# wsoc_wgcm_secure register map
Vendor: Texas Instruments
Peripheral module from a debugger description file (folder CC35X1).
Registers are 32-bit, read-write, no defined reset value unless marked. A register's access mark holds for its fields unless they carry their own. Offsets are as the file gives them; lines under a group give offsets from that group; [hi:lo] are bit positions; {n}, {i} and the like mark numbered series; 'fields as' and 'values as' point back to an identical list; <NAME> marks a mode.

## wsoc_wgcm_secure
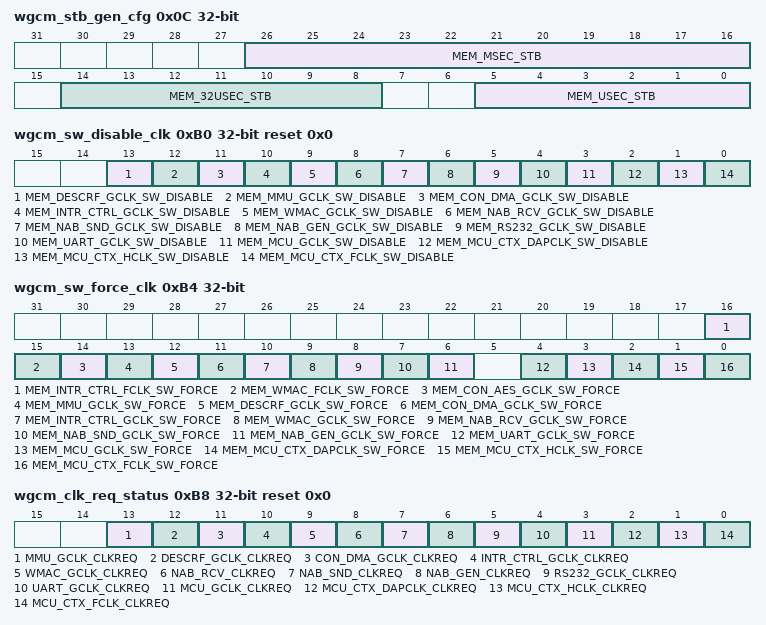
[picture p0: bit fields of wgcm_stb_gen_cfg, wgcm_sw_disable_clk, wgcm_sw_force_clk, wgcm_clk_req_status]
0x0C wgcm_stb_gen_cfg access per field — configuration of usec strobe value represent number of main ocp clocks per usec strobe. if clock frequency changes, the usec strobe will drift with it.
  [26:16] MEM_MSEC_STB rw — number of usec stb used in order to generage a 1 msec period
  [14:8] MEM_32USEC_STB rw — number of usec_stb to count per pulse. cfg should be 1 less than required (31 for 32 usec)
  [5:0] MEM_USEC_STB rw — number of wsoc ocp clocks to count per usec. (cfg should be 1 less that required - 19 for 20 clocks)
0x2C gns_spare_reg access per field — clock enable for the BLE. 0 - clock disabled. 1 - clock enabled.
  [7:0] MEM_GNS_SPARE rw
{0x40+8i} gns_notification_{i}_value (i=0..3)
  [31:0] MEM_GNS_NOTIF_{i}_VALUE
{0x44+8i} gns_notification_{i}_enable (i=0..3)
  [31:0] MEM_GNS_NOTIF_{i}_EN
0x60 gns_notification_status access per field
  [3:0] MEM_GNS_NOTIF_STATUS_RDCL rw — Bit 0 - gns notification 0 Bit 1 - gns notification 1 Bit 2 - gns notification 2 Bit 3 - gns notification 3
0x70 gns_raw_status ro reset 0x0 — GNS_RAW_STATUS - LSB (31:0) [ 0] = wgcm_in_nab_is_pending_recv_or_evt [ 1] = wgcm_in_nab_is_busy [ 2] = wgcm_in_descrf_rx_nab_done_qne [ 3] = |mem_wgcm_in_sw_src[3:0] [ 4] = wgcm_wrapper_is_busy [ 5] = mem_force_core_on [ 6] = ble_gns_busy [ 7] = debugss_core_forceactive [ 8] = queue_not_empty_m0_sw_usage_irq[0] [ 9] = queue_not_empty_m0_sw_usage_irq[1] [10] = queue_not_empty_m0_sw_usage_irq[2] [11] = queue_not_empty_m0_sw_usage_irq[3] [12] = queue_not_empty_m0_sw_usage_irq[4] [13] = queue_not_empty_m0_sw_usage_irq[5] [14] = queue_not_empty_m0_sw_usage_irq[6] [15] = queue_not_empty_m0_sw_usage_irq[7] [16] = queue_not_empty_m0_sw_usage_irq[8] [17] = queue_not_empty_m0_sw_usage_irq[9] [18] = queue_not_empty_m3_sw_usage_irq[0] [19] = queue_not_empty_m3_sw_usage_irq[1] [20] = queue_not_empty_m3_sw_usage_irq[2] [21] = queue_not_empty_m3_sw_usage_irq[3] [22] = queue_not_empty_m3_sw_usage_irq[4] [23] = queue_not_empty_m3_sw_usage_irq[5] [24] = queue_not_empty_m3_sw_usage_irq[6] [25] = queue_not_empty_m3_sw_usage_irq[7] [26] = queue_not_empty_m3_sw_usage_irq[8] [27] = hif_tx_busy [28] = hif_rx_busy [29] = hif_dma_active [30] = hif_fifo_not_empty [31] = gns_in_uart_fifo_not_empty
  [31:0] GNS_RAW_STATUS_RDCL — Bit 31
0x74 gns_host_if_trigger ro
  [31:0] MEM_GNS_HOST_IF_TRIGGER_RDCL — [ 0] = wgcm_in_nab_is_pending_recv_or_evt [ 1] = wgcm_in_nab_is_busy [ 2] = wgcm_in_descrf_rx_nab_done_qne [ 3] = |mem_wgcm_in_sw_src[3:0] [ 4] = wgcm_wrapper_is_busy [ 5] = mem_force_core_on [ 6] = ble_gns_busy [ 7] = debugss_core_forceactive [ 8] = queue_not_empty_m0_sw_usage_irq[0] [ 9] = queue_not_empty_m0_sw_usage_irq[1] [10] = queue_not_empty_m0_sw_usage_irq[2] [11] = queue_not_empty_m0_sw_usage_irq[3] [12] = queue_not_empty_m0_sw_usage_irq[4] [13] = queue_not_empty_m0_sw_usage_irq[5] [14] = queue_not_empty_m0_sw_usage_irq[6] [15] = queue_not_empty_m0_sw_usage_irq[7] [16] = queue_not_empty_m0_sw_usage_irq[8] [17] = queue_not_empty_m0_sw_usage_irq[9] [18] = queue_not_empty_m3_sw_usage_irq[0] [19] = queue_not_empty_m3_sw_usage_irq[1] [20] = queue_not_empty_m3_sw_usage_irq[2] [21] = queue_not_empty_m3_sw_usage_irq[3] [22] = queue_not_empty_m3_sw_usage_irq[4] [23] = queue_not_empty_m3_sw_usage_irq[5] [24] = queue_not_empty_m3_sw_usage_irq[6] [25] = queue_not_empty_m3_sw_usage_irq[7] [26] = queue_not_empty_m3_sw_usage_irq[8] [27] = hif_tx_busy [28] = hif_rx_busy [29] = hif_dma_active [30] = hif_fifo_not_empty [31] = gns_in_uart_fifo_not_empty
0x78 gns_host_if_lock access per field
  [0] MEM_GNS_HOST_IF_LOCK_WROPT rw — HOST Lock Status 1 - HOST I/F is locked (Default) 0 - HOST I/F is active This field initiate as "loced", it can be written directly or latched "loced" ('0') while reading "HOST_IF_TRIGGER" field and the field is zero
0x80 gns_host_if_en
  [31:0] MEM_GNS_HOST_IF_EN
0x84 gns_notification_cfg access per field
  [3:0] MEM_GNS_NOTIF_CFG rw — each bit per notification status bit 0 - AND - Notification set uppon all bit are equal 1 - OR - Notification set uppon at least one bit is equal Please note : mode "OR" use de-morgan" trick so need to negate the "...NOTIFICATION_x_ENABLE"
{0x88+8i} gns_notification_{i}_value_63_32 (i=0..3)
  [31:0] MEM_GNS_NOTIF_{i}_VALUE_63_32
{0x8C+8i} gns_notification_{i}_enable_63_32 (i=0..3)
  [31:0] MEM_GNS_NOTIF_{i}_EN_63_32
0xA8 gns_raw_status_63_32 ro reset 0x0 — GNS_RAW_STATUS - MSB (63:32) [ 0] = wgcm_in_descrf_txdq_ac_qne [ 1] = wgcm_in_descrf_txdq_qne [ 2] = wgcm_in_wmac_pmac_ind_TBD [ 3] = wgcm_in_wmac_rx_main_is_busy [ 4] = wgcm_in_wmac_rxip [ 5] = wgcm_in_wmac_rip [ 6] = wgcm_in_wmac_any_ac_ctrl_is_busy [ 7] = wgcm_in_wmac_tx_main_is_busy [ 8] = wgcm_in_wmac_txip [ 9] = wgcm_in_wmac_tip [10] = wgcm_in_wmac_any_qv_high [11] = wgcm_in_descrf_mmu_dealloc_qne [12] = wgcm_in_mmu_request_pending [13] = wgcm_in_descrf_tx_exch_hi_prio_qne [14] = wgcm_in_descrf_tx_exch_qne [15] = wgcm_in_descrf_rx_complete_qne [16] = wgcm_in_wmac_tb_seq_evt [17] = wgcm_in_wmac_imm_rsp_seq_evt [18] = wgcm_in_wmac_wait_for_imm_rsp_evt [19] = wgcm_in_wmac_bf_seq_evt [20] = mem_wgcm_in_sw_src[ 4] [21] = mem_wgcm_in_sw_src[ 5] [22] = mem_wgcm_in_sw_src[ 6] [23] = mem_wgcm_in_sw_src[ 7] [24] = mem_wgcm_in_sw_src[ 8] [25] = mem_wgcm_in_sw_src[ 9] [26] = mem_wgcm_in_sw_src[10] [27] = mem_wgcm_in_sw_src[11] [28] = mem_wgcm_in_sw_src[12] [29] = mem_wgcm_in_sw_src[13] [30] = mem_wgcm_in_sw_src[14] [31] = mem_wgcm_in_sw_src[15]
0xAC gns_raw_status_63_32_lock ro
0xB0 wgcm_sw_disable_clk access per field reset 0x0 — Disable clk (even if clk_request is '1').
  [13] MEM_DESCRF_GCLK_SW_DISABLE rw, [12] MEM_MMU_GCLK_SW_DISABLE rw, [11] MEM_CON_DMA_GCLK_SW_DISABLE rw, [10] MEM_INTR_CTRL_GCLK_SW_DISABLE rw, [9] MEM_WMAC_GCLK_SW_DISABLE rw, [8] MEM_NAB_RCV_GCLK_SW_DISABLE rw, [7] MEM_NAB_SND_GCLK_SW_DISABLE rw, [6] MEM_NAB_GEN_GCLK_SW_DISABLE rw, [5] MEM_RS232_GCLK_SW_DISABLE rw, [4] MEM_UART_GCLK_SW_DISABLE rw, [3] MEM_MCU_GCLK_SW_DISABLE rw, [2] MEM_MCU_CTX_DAPCLK_SW_DISABLE rw, [1] MEM_MCU_CTX_HCLK_SW_DISABLE rw, [0] MEM_MCU_CTX_FCLK_SW_DISABLE rw
0xB4 wgcm_sw_force_clk access per field — Force clk (even if fw_disable_clk is '1' or clk_request is '0').
  [16] MEM_INTR_CTRL_FCLK_SW_FORCE rw, [15] MEM_WMAC_FCLK_SW_FORCE rw, [14] MEM_CON_AES_GCLK_SW_FORCE rw, [13] MEM_MMU_GCLK_SW_FORCE rw, [12] MEM_DESCRF_GCLK_SW_FORCE rw, [11] MEM_CON_DMA_GCLK_SW_FORCE rw, [10] MEM_INTR_CTRL_GCLK_SW_FORCE rw, [9] MEM_WMAC_GCLK_SW_FORCE rw, [8] MEM_NAB_RCV_GCLK_SW_FORCE rw, [7] MEM_NAB_SND_GCLK_SW_FORCE rw, [6] MEM_NAB_GEN_GCLK_SW_FORCE rw, [4] MEM_UART_GCLK_SW_FORCE rw, [3] MEM_MCU_GCLK_SW_FORCE rw, [2] MEM_MCU_CTX_DAPCLK_SW_FORCE rw, [1] MEM_MCU_CTX_HCLK_SW_FORCE rw, [0] MEM_MCU_CTX_FCLK_SW_FORCE rw
0xB8 wgcm_clk_req_status access not given reset 0x0 — busy/clock request indication from sub-modules.
  [13] MMU_GCLK_CLKREQ ro, [12] DESCRF_GCLK_CLKREQ ro, [11] CON_DMA_GCLK_CLKREQ ro, [10] INTR_CTRL_GCLK_CLKREQ ro, [9] WMAC_GCLK_CLKREQ ro, [8] NAB_RCV_CLKREQ ro, [7] NAB_SND_CLKREQ ro, [6] NAB_GEN_CLKREQ ro, [5] RS232_GCLK_CLKREQ ro, [4] UART_GCLK_CLKREQ ro, [3] MCU_GCLK_CLKREQ ro, [2] MCU_CTX_DAPCLK_CLKREQ ro, [1] MCU_CTX_HCLK_CLKREQ ro, [0] MCU_CTX_FCLK_CLKREQ ro
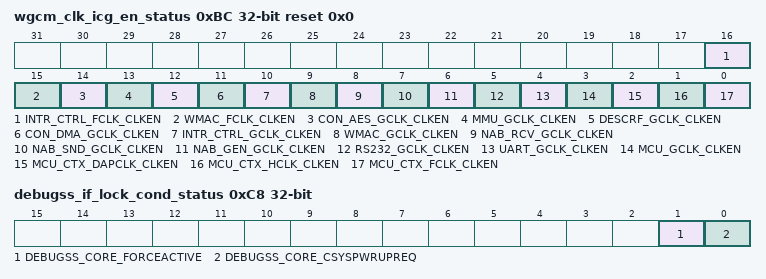
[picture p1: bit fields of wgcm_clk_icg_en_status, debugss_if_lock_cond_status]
0xBC wgcm_clk_icg_en_status access not given reset 0x0 — ICG Enable value.
  [16] INTR_CTRL_FCLK_CLKEN ro, [15] WMAC_FCLK_CLKEN ro, [14] CON_AES_GCLK_CLKEN ro, [13] MMU_GCLK_CLKEN ro, [12] DESCRF_GCLK_CLKEN ro, [11] CON_DMA_GCLK_CLKEN ro, [10] INTR_CTRL_GCLK_CLKEN ro, [9] WMAC_GCLK_CLKEN ro, [8] NAB_RCV_GCLK_CLKEN ro, [7] NAB_SND_GCLK_CLKEN ro, [6] NAB_GEN_GCLK_CLKEN ro, [5] RS232_GCLK_CLKEN ro, [4] UART_GCLK_CLKEN ro, [3] MCU_GCLK_CLKEN ro, [2] MCU_CTX_DAPCLK_CLKEN ro, [1] MCU_CTX_HCLK_CLKEN ro, [0] MCU_CTX_FCLK_CLKEN ro
0xC0 debugss_if_lock access per field — The method: Obtain lock by Read. Following are all s/w operation possibilities: When reading '1' - lock is obtained. (i.e. no debugss request was active during the rd transaction). When reading '0' - lock is not obtained. Try to read again. (i.e. at least debugss request event was active during the rd transaction). when writing '1' - lock will be obtained regardless to debugss request status when writing '0' - lock will be released.
  [0] DEBUGSS_IF_LOCK_WRDCL rw
0xC4 debugss_if_lock_cond_mask access per field — Bit 0 - Masks DEBUGSS CSYSPWRUPREQ. Bit 1 - Masks DEBUGSS FORCEACTIVE. Set 1 - Mask request during lock check. Set 0 - O.W.
  [1:0] MEM_DEBUGSS_IF_LOCK_COND_MASK rw
0xC8 debugss_if_lock_cond_status ro
  [1] DEBUGSS_CORE_FORCEACTIVE, [0] DEBUGSS_CORE_CSYSPWRUPREQ
0xCC debugss_pwrdwndesired access per field — SW shall set this bit to inform debugger that it trying to go power down but FORCEACTIVE/SYSPWRUPREQ is set (i.e. debugss i/f lock is failing).
  [0] MEM_CORE_DEBUGSS_PWRDWNDESIRED rw
